# IPE3_BFSW_ICONT register map
Vendor: Texas Instruments
Peripheral module from a debugger description file (folder DRA74xP_75xP_76xP_77xP).
Registers are 32-bit, access per field, reset 0x0 unless marked. A register's access mark holds for its fields unless they carry their own. Offsets are as the file gives them; lines under a group give offsets from that group; [hi:lo] are bit positions; {n}, {i} and the like mark numbered series; 'fields as' and 'values as' point back to an identical list; <NAME> marks a mode.

## IPE3_BFSW_ICONT
0x00 IPE3_BFSW_VIEWMODE
  [0] VIEW_IPORGBUF rw — View mode selection for iporgbuf 0: Full view mode is selected. 1: Ping-pong view mode is selected.
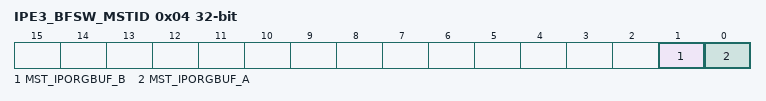
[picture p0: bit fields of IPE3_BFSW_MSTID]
0x04 IPE3_BFSW_MSTID — Master ID 1 register. Selects master (HWA or DMA bus). This register is used in both full view and ping-pong view mode. This register is for buffers that have two physical memories. This register is affected by direct_switch_pi input port.
  [1] MST_IPORGBUF_B rw — Master selection for iporgbuf B. This bit is used only in ping-pong view mode. 0: Buffer B is assigned to DMA. 1: Buffer B is assigned to HWA This bit has no effect in full-view mode. If direct_switch_pi is high, the value of this bit is inverted.
  [0] MST_IPORGBUF_A rw — Master selection for iporgbuf A. This bit is used in full-view mode and ping-pong view mode. In full-view mode: 0: Buffers A and B are assigned to DMA. 1: Buffers A and B are assigned to HWA. In ping-pong view mode: 0: Buffer A is assigned to DMA. 1: Buffer A is assigned to HWA. (Buffer B is not affected in ping-pong view mode.) If direct_switch_pi is high, the value of this bit is inverted.
